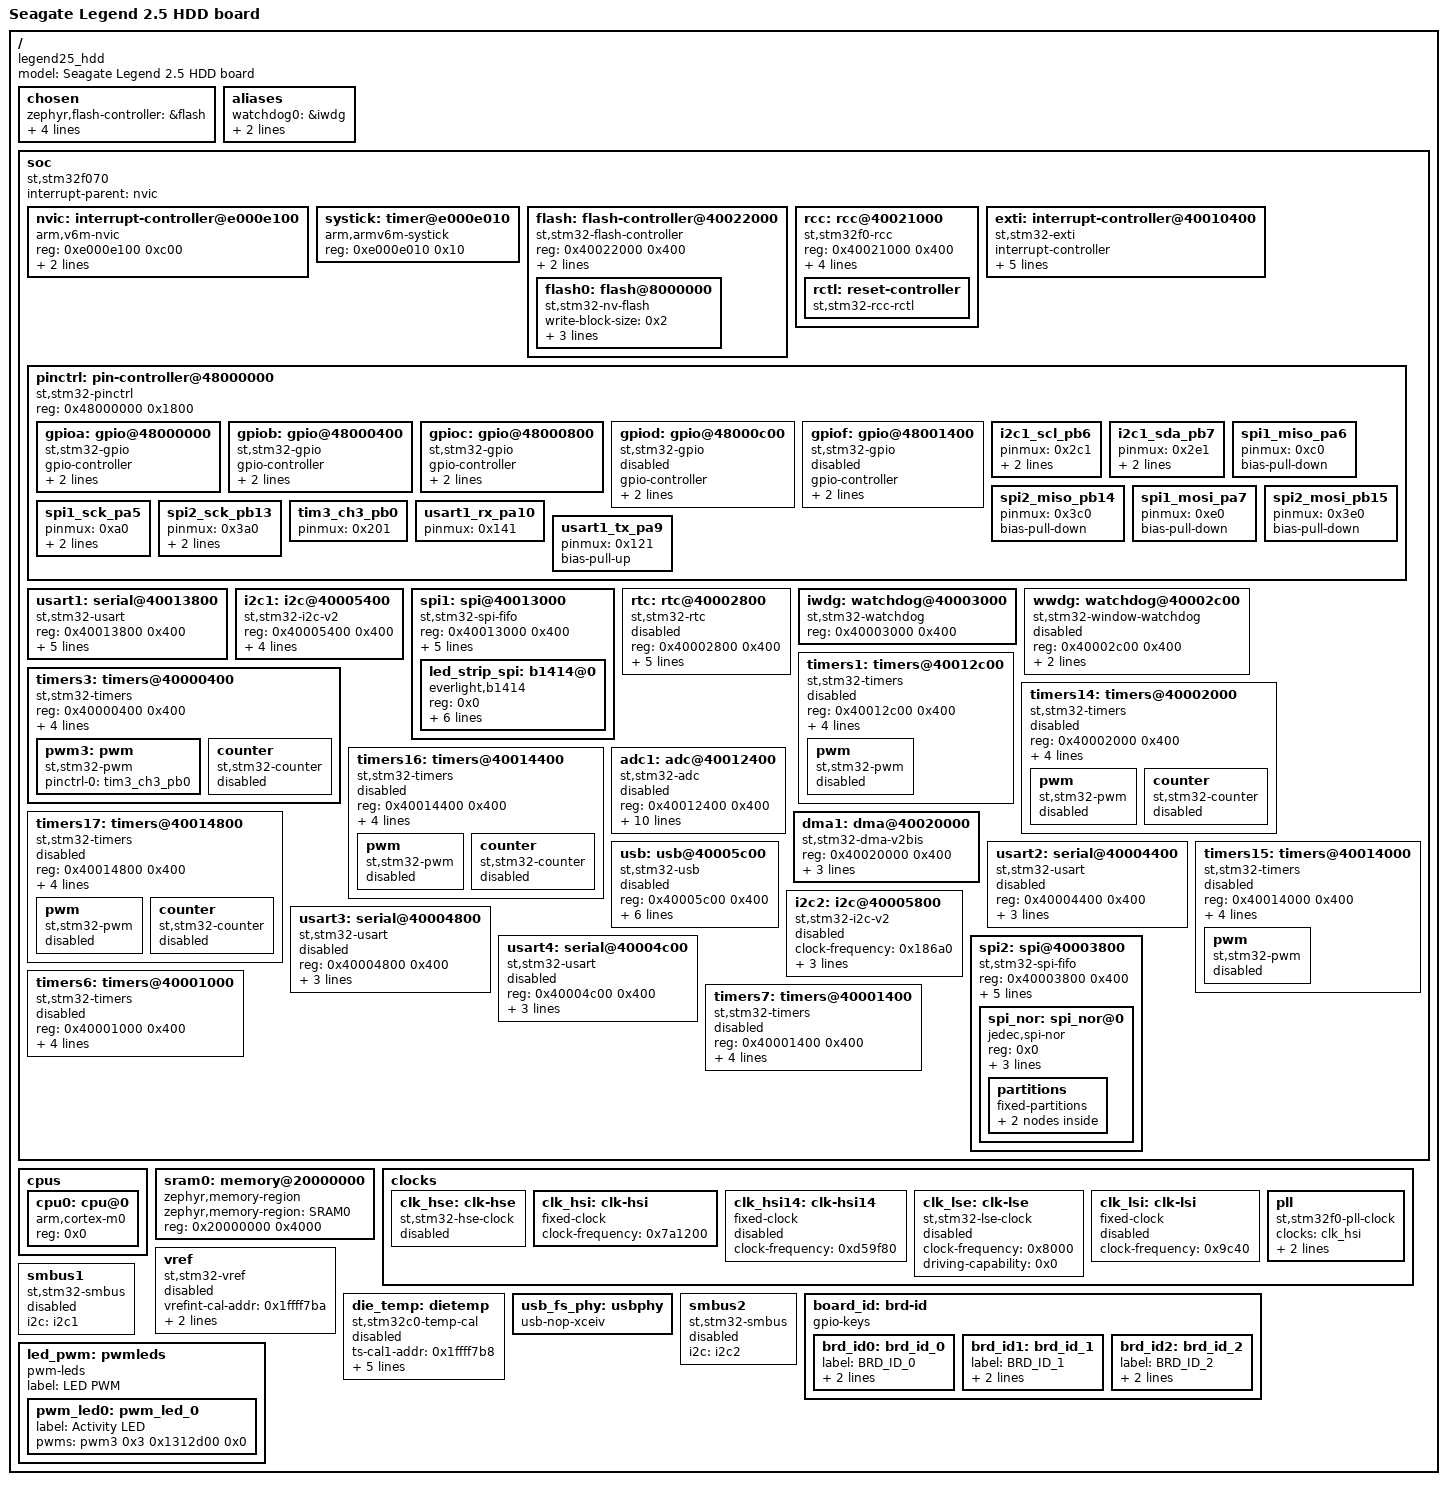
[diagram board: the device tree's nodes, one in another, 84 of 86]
/dts-v1/;

/* node '/' defined in zephyr/dts/common/skeleton.dtsi:9 */
/ {
	#address-cells = < 0x1 >;               /* in zephyr/dts/common/skeleton.dtsi:10 */
	#size-cells = < 0x1 >;                  /* in zephyr/dts/common/skeleton.dtsi:11 */
	model = "Seagate Legend 2.5 HDD board"; /* in zephyr/boards/seagate/legend/legend_stm32f070xb_25hdd.overlay:8 */
	compatible = "legend25_hdd",
	             "seagate,legend25_hdd";    /* in zephyr/boards/seagate/legend/legend_stm32f070xb_25hdd.overlay:9 */

	/* node '/chosen' defined in zephyr/dts/common/skeleton.dtsi:13 */
	chosen {
		zephyr,flash-controller = &flash; /* in zephyr/dts/arm/st/f0/stm32f0.dtsi:24 */
		zephyr,console = &usart1;         /* in zephyr/boards/seagate/legend/legend.dts:16 */
		zephyr,shell-uart = &usart1;      /* in zephyr/boards/seagate/legend/legend.dts:17 */
		zephyr,sram = &sram0;             /* in zephyr/boards/seagate/legend/legend.dts:18 */
		zephyr,flash = &flash0;           /* in zephyr/boards/seagate/legend/legend.dts:19 */
	};

	/* node '/aliases' defined in zephyr/dts/common/skeleton.dtsi:15 */
	aliases {
		watchdog0 = &iwdg;          /* in zephyr/boards/seagate/legend/legend.dts:23 */
		led-strip = &led_strip_spi; /* in zephyr/boards/seagate/legend/legend.dts:24 */
		pwm-led0 = &pwm_led0;       /* in zephyr/boards/seagate/legend/legend_stm32f070xb_25hdd.overlay:12 */
	};

	/* node '/soc' defined in zephyr/dts/arm/armv6-m.dtsi:6 */
	soc {
		#address-cells = < 0x1 >;     /* in zephyr/dts/arm/armv6-m.dtsi:7 */
		#size-cells = < 0x1 >;        /* in zephyr/dts/arm/armv6-m.dtsi:8 */
		interrupt-parent = < &nvic >; /* in zephyr/dts/arm/armv6-m.dtsi:10 */
		ranges;                       /* in zephyr/dts/arm/armv6-m.dtsi:11 */
		compatible = "st,stm32f070",
		             "st,stm32f0",
		             "simple-bus";    /* in zephyr/dts/arm/st/f0/stm32f070.dtsi:11 */

		/* node '/soc/interrupt-controller@e000e100' defined in zephyr/dts/arm/armv6-m.dtsi:13 */
		nvic: interrupt-controller@e000e100 {
			#address-cells = < 0x1 >;            /* in zephyr/dts/arm/armv6-m.dtsi:14 */
			compatible = "arm,v6m-nvic";         /* in zephyr/dts/arm/armv6-m.dtsi:15 */
			reg = < 0xe000e100 0xc00 >;          /* in zephyr/dts/arm/armv6-m.dtsi:16 */
			interrupt-controller;                /* in zephyr/dts/arm/armv6-m.dtsi:17 */
			#interrupt-cells = < 0x2 >;          /* in zephyr/dts/arm/armv6-m.dtsi:18 */
			arm,num-irq-priority-bits = < 0x2 >; /* in zephyr/dts/arm/st/f0/stm32f0.dtsi:393 */
			phandle = < 0x1 >;                   /* in zephyr/dts/arm/armv6-m.dtsi:10 */
		};

		/* node '/soc/timer@e000e010' defined in zephyr/dts/arm/armv6-m.dtsi:21 */
		systick: timer@e000e010 {
			compatible = "arm,armv6m-systick"; /* in zephyr/dts/arm/armv6-m.dtsi:22 */
			reg = < 0xe000e010 0x10 >;         /* in zephyr/dts/arm/armv6-m.dtsi:23 */
		};

		/* node '/soc/flash-controller@40022000' defined in zephyr/dts/arm/st/f0/stm32f0.dtsi:87 */
		flash: flash-controller@40022000 {
			compatible = "st,stm32-flash-controller",
			             "st,stm32f1-flash-controller"; /* in zephyr/dts/arm/st/f0/stm32f0.dtsi:88 */
			reg = < 0x40022000 0x400 >;                 /* in zephyr/dts/arm/st/f0/stm32f0.dtsi:89 */
			interrupts = < 0x3 0x0 >;                   /* in zephyr/dts/arm/st/f0/stm32f0.dtsi:90 */
			clocks = < &rcc 0x14 0x10 >;                /* in zephyr/dts/arm/st/f0/stm32f0.dtsi:91 */
			#address-cells = < 0x1 >;                   /* in zephyr/dts/arm/st/f0/stm32f0.dtsi:93 */
			#size-cells = < 0x1 >;                      /* in zephyr/dts/arm/st/f0/stm32f0.dtsi:94 */

			/* node '/soc/flash-controller@40022000/flash@8000000' defined in zephyr/dts/arm/st/f0/stm32f0.dtsi:96 */
			flash0: flash@8000000 {
				compatible = "st,stm32-nv-flash",
				             "soc-nv-flash";      /* in zephyr/dts/arm/st/f0/stm32f0.dtsi:97 */
				write-block-size = < 0x2 >;       /* in zephyr/dts/arm/st/f0/stm32f0.dtsi:99 */
				max-erase-time = < 0x28 >;        /* in zephyr/dts/arm/st/f0/stm32f0.dtsi:101 */
				erase-block-size = < 0x800 >;     /* in zephyr/dts/arm/st/f0/stm32f070Xb.dtsi:16 */
				reg = < 0x8000000 0x20000 >;      /* in zephyr/dts/arm/st/f0/stm32f070Xb.dtsi:17 */
			};
		};

		/* node '/soc/rcc@40021000' defined in zephyr/dts/arm/st/f0/stm32f0.dtsi:105 */
		rcc: rcc@40021000 {
			compatible = "st,stm32f0-rcc";   /* in zephyr/dts/arm/st/f0/stm32f0.dtsi:106 */
			#clock-cells = < 0x2 >;          /* in zephyr/dts/arm/st/f0/stm32f0.dtsi:107 */
			reg = < 0x40021000 0x400 >;      /* in zephyr/dts/arm/st/f0/stm32f0.dtsi:108 */
			clocks = < &pll >;               /* in zephyr/boards/seagate/legend/legend_stm32f070xb_25hdd.overlay:38 */
			clock-frequency = < 0x2dc6c00 >; /* in zephyr/boards/seagate/legend/legend_stm32f070xb_25hdd.overlay:39 */
			ahb-prescaler = < 0x1 >;         /* in zephyr/boards/seagate/legend/legend_stm32f070xb_25hdd.overlay:40 */
			apb1-prescaler = < 0x1 >;        /* in zephyr/boards/seagate/legend/legend_stm32f070xb_25hdd.overlay:41 */
			phandle = < 0x2 >;               /* in zephyr/dts/arm/st/f0/stm32f0.dtsi:91 */

			/* node '/soc/rcc@40021000/reset-controller' defined in zephyr/dts/arm/st/f0/stm32f0.dtsi:110 */
			rctl: reset-controller {
				compatible = "st,stm32-rcc-rctl"; /* in zephyr/dts/arm/st/f0/stm32f0.dtsi:111 */
				#reset-cells = < 0x1 >;           /* in zephyr/dts/arm/st/f0/stm32f0.dtsi:112 */
				phandle = < 0x4 >;                /* in zephyr/dts/arm/st/f0/stm32f0.dtsi:180 */
			};
		};

		/* node '/soc/interrupt-controller@40010400' defined in zephyr/dts/arm/st/f0/stm32f0.dtsi:116 */
		exti: interrupt-controller@40010400 {
			compatible = "st,stm32-exti"; /* in zephyr/dts/arm/st/f0/stm32f0.dtsi:117 */
			interrupt-controller;         /* in zephyr/dts/arm/st/f0/stm32f0.dtsi:118 */
			#interrupt-cells = < 0x1 >;   /* in zephyr/dts/arm/st/f0/stm32f0.dtsi:119 */
			#address-cells = < 0x0 >;     /* in zephyr/dts/arm/st/f0/stm32f0.dtsi:120 */
			reg = < 0x40010400 0x400 >;   /* in zephyr/dts/arm/st/f0/stm32f0.dtsi:121 */
			clocks = < &rcc 0x18 0x1 >;   /* in zephyr/dts/arm/st/f0/stm32f0.dtsi:122 */
			num-lines = < 0x20 >;         /* in zephyr/dts/arm/st/f0/stm32f0.dtsi:123 */
			interrupts = < 0x5 0x0 >,
			             < 0x6 0x0 >,
			             < 0x7 0x0 >;     /* in zephyr/dts/arm/st/f0/stm32f0.dtsi:124 */
			interrupt-names = "line0-1",
			                  "line2-3",
			                  "line4-15"; /* in zephyr/dts/arm/st/f0/stm32f0.dtsi:125 */
			line-ranges = < 0x0 0x2 >,
			              < 0x2 0x2 >,
			              < 0x4 0xc >;    /* in zephyr/dts/arm/st/f0/stm32f0.dtsi:126 */
		};

		/* node '/soc/pin-controller@48000000' defined in zephyr/dts/arm/st/f0/stm32f0.dtsi:129 */
		pinctrl: pin-controller@48000000 {
			compatible = "st,stm32-pinctrl"; /* in zephyr/dts/arm/st/f0/stm32f0.dtsi:130 */
			#address-cells = < 0x1 >;        /* in zephyr/dts/arm/st/f0/stm32f0.dtsi:131 */
			#size-cells = < 0x1 >;           /* in zephyr/dts/arm/st/f0/stm32f0.dtsi:132 */
			reg = < 0x48000000 0x1800 >;     /* in zephyr/dts/arm/st/f0/stm32f0.dtsi:133 */

			/* node '/soc/pin-controller@48000000/gpio@48000000' defined in zephyr/dts/arm/st/f0/stm32f0.dtsi:135 */
			gpioa: gpio@48000000 {
				compatible = "st,stm32-gpio";   /* in zephyr/dts/arm/st/f0/stm32f0.dtsi:136 */
				gpio-controller;                /* in zephyr/dts/arm/st/f0/stm32f0.dtsi:137 */
				#gpio-cells = < 0x2 >;          /* in zephyr/dts/arm/st/f0/stm32f0.dtsi:138 */
				reg = < 0x48000000 0x400 >;     /* in zephyr/dts/arm/st/f0/stm32f0.dtsi:139 */
				clocks = < &rcc 0x14 0x20000 >; /* in zephyr/dts/arm/st/f0/stm32f0.dtsi:140 */
			};

			/* node '/soc/pin-controller@48000000/gpio@48000400' defined in zephyr/dts/arm/st/f0/stm32f0.dtsi:143 */
			gpiob: gpio@48000400 {
				compatible = "st,stm32-gpio";   /* in zephyr/dts/arm/st/f0/stm32f0.dtsi:144 */
				gpio-controller;                /* in zephyr/dts/arm/st/f0/stm32f0.dtsi:145 */
				#gpio-cells = < 0x2 >;          /* in zephyr/dts/arm/st/f0/stm32f0.dtsi:146 */
				reg = < 0x48000400 0x400 >;     /* in zephyr/dts/arm/st/f0/stm32f0.dtsi:147 */
				clocks = < &rcc 0x14 0x40000 >; /* in zephyr/dts/arm/st/f0/stm32f0.dtsi:148 */
				phandle = < 0x12 >;             /* in zephyr/boards/seagate/legend/legend.dts:91 */
			};

			/* node '/soc/pin-controller@48000000/gpio@48000800' defined in zephyr/dts/arm/st/f0/stm32f0.dtsi:151 */
			gpioc: gpio@48000800 {
				compatible = "st,stm32-gpio";   /* in zephyr/dts/arm/st/f0/stm32f0.dtsi:152 */
				gpio-controller;                /* in zephyr/dts/arm/st/f0/stm32f0.dtsi:153 */
				#gpio-cells = < 0x2 >;          /* in zephyr/dts/arm/st/f0/stm32f0.dtsi:154 */
				reg = < 0x48000800 0x400 >;     /* in zephyr/dts/arm/st/f0/stm32f0.dtsi:155 */
				clocks = < &rcc 0x14 0x80000 >; /* in zephyr/dts/arm/st/f0/stm32f0.dtsi:156 */
				phandle = < 0x17 >;             /* in zephyr/boards/seagate/legend/legend.dts:32 */
			};

			/* node '/soc/pin-controller@48000000/gpio@48000c00' defined in zephyr/dts/arm/st/f0/stm32f0.dtsi:159 */
			gpiod: gpio@48000c00 {
				compatible = "st,stm32-gpio";    /* in zephyr/dts/arm/st/f0/stm32f0.dtsi:160 */
				gpio-controller;                 /* in zephyr/dts/arm/st/f0/stm32f0.dtsi:161 */
				#gpio-cells = < 0x2 >;           /* in zephyr/dts/arm/st/f0/stm32f0.dtsi:162 */
				reg = < 0x48000c00 0x400 >;      /* in zephyr/dts/arm/st/f0/stm32f0.dtsi:163 */
				clocks = < &rcc 0x14 0x100000 >; /* in zephyr/dts/arm/st/f0/stm32f0.dtsi:164 */
				status = "disabled";             /* in zephyr/boards/seagate/legend/legend.dts:195 */
			};

			/* node '/soc/pin-controller@48000000/gpio@48001400' defined in zephyr/dts/arm/st/f0/stm32f0.dtsi:167 */
			gpiof: gpio@48001400 {
				compatible = "st,stm32-gpio";    /* in zephyr/dts/arm/st/f0/stm32f0.dtsi:168 */
				gpio-controller;                 /* in zephyr/dts/arm/st/f0/stm32f0.dtsi:169 */
				#gpio-cells = < 0x2 >;           /* in zephyr/dts/arm/st/f0/stm32f0.dtsi:170 */
				reg = < 0x48001400 0x400 >;      /* in zephyr/dts/arm/st/f0/stm32f0.dtsi:171 */
				clocks = < &rcc 0x14 0x400000 >; /* in zephyr/dts/arm/st/f0/stm32f0.dtsi:172 */
				status = "disabled";             /* in zephyr/boards/seagate/legend/legend.dts:199 */
			};

			/* node '/soc/pin-controller@48000000/i2c1_scl_pb6' defined in modules/hal/stm32/dts/st/f0/stm32f070cbtx-pinctrl.dtsi:207 */
			i2c1_scl_pb6: i2c1_scl_pb6 {
				pinmux = < 0x2c1 >; /* in modules/hal/stm32/dts/st/f0/stm32f070cbtx-pinctrl.dtsi:208 */
				bias-pull-up;       /* in modules/hal/stm32/dts/st/f0/stm32f070cbtx-pinctrl.dtsi:209 */
				drive-open-drain;   /* in modules/hal/stm32/dts/st/f0/stm32f070cbtx-pinctrl.dtsi:210 */
				phandle = < 0x7 >;  /* in zephyr/boards/seagate/legend/legend.dts:58 */
			};

			/* node '/soc/pin-controller@48000000/i2c1_sda_pb7' defined in modules/hal/stm32/dts/st/f0/stm32f070cbtx-pinctrl.dtsi:233 */
			i2c1_sda_pb7: i2c1_sda_pb7 {
				pinmux = < 0x2e1 >; /* in modules/hal/stm32/dts/st/f0/stm32f070cbtx-pinctrl.dtsi:234 */
				bias-pull-up;       /* in modules/hal/stm32/dts/st/f0/stm32f070cbtx-pinctrl.dtsi:235 */
				drive-open-drain;   /* in modules/hal/stm32/dts/st/f0/stm32f070cbtx-pinctrl.dtsi:236 */
				phandle = < 0x8 >;  /* in zephyr/boards/seagate/legend/legend.dts:58 */
			};

			/* node '/soc/pin-controller@48000000/spi1_miso_pa6' defined in modules/hal/stm32/dts/st/f0/stm32f070cbtx-pinctrl.dtsi:283 */
			spi1_miso_pa6: spi1_miso_pa6 {
				pinmux = < 0xc0 >; /* in modules/hal/stm32/dts/st/f0/stm32f070cbtx-pinctrl.dtsi:284 */
				bias-pull-down;    /* in modules/hal/stm32/dts/st/f0/stm32f070cbtx-pinctrl.dtsi:285 */
				phandle = < 0xa >; /* in zephyr/boards/seagate/legend/legend.dts:65 */
			};

			/* node '/soc/pin-controller@48000000/spi2_miso_pb14' defined in modules/hal/stm32/dts/st/f0/stm32f070cbtx-pinctrl.dtsi:293 */
			spi2_miso_pb14: spi2_miso_pb14 {
				pinmux = < 0x3c0 >; /* in modules/hal/stm32/dts/st/f0/stm32f070cbtx-pinctrl.dtsi:294 */
				bias-pull-down;     /* in modules/hal/stm32/dts/st/f0/stm32f070cbtx-pinctrl.dtsi:295 */
				phandle = < 0x10 >; /* in zephyr/boards/seagate/legend/legend.dts:89 */
			};

			/* node '/soc/pin-controller@48000000/spi1_mosi_pa7' defined in modules/hal/stm32/dts/st/f0/stm32f070cbtx-pinctrl.dtsi:300 */
			spi1_mosi_pa7: spi1_mosi_pa7 {
				pinmux = < 0xe0 >; /* in modules/hal/stm32/dts/st/f0/stm32f070cbtx-pinctrl.dtsi:301 */
				bias-pull-down;    /* in modules/hal/stm32/dts/st/f0/stm32f070cbtx-pinctrl.dtsi:302 */
				phandle = < 0xb >; /* in zephyr/boards/seagate/legend/legend.dts:65 */
			};

			/* node '/soc/pin-controller@48000000/spi2_mosi_pb15' defined in modules/hal/stm32/dts/st/f0/stm32f070cbtx-pinctrl.dtsi:310 */
			spi2_mosi_pb15: spi2_mosi_pb15 {
				pinmux = < 0x3e0 >; /* in modules/hal/stm32/dts/st/f0/stm32f070cbtx-pinctrl.dtsi:311 */
				bias-pull-down;     /* in modules/hal/stm32/dts/st/f0/stm32f070cbtx-pinctrl.dtsi:312 */
				phandle = < 0x11 >; /* in zephyr/boards/seagate/legend/legend.dts:89 */
			};

			/* node '/soc/pin-controller@48000000/spi1_sck_pa5' defined in modules/hal/stm32/dts/st/f0/stm32f070cbtx-pinctrl.dtsi:339 */
			spi1_sck_pa5: spi1_sck_pa5 {
				pinmux = < 0xa0 >;             /* in modules/hal/stm32/dts/st/f0/stm32f070cbtx-pinctrl.dtsi:340 */
				bias-pull-down;                /* in modules/hal/stm32/dts/st/f0/stm32f070cbtx-pinctrl.dtsi:341 */
				slew-rate = "very-high-speed"; /* in modules/hal/stm32/dts/st/f0/stm32f070cbtx-pinctrl.dtsi:342 */
				phandle = < 0x9 >;             /* in zephyr/boards/seagate/legend/legend.dts:65 */
			};

			/* node '/soc/pin-controller@48000000/spi2_sck_pb13' defined in modules/hal/stm32/dts/st/f0/stm32f070cbtx-pinctrl.dtsi:357 */
			spi2_sck_pb13: spi2_sck_pb13 {
				pinmux = < 0x3a0 >;            /* in modules/hal/stm32/dts/st/f0/stm32f070cbtx-pinctrl.dtsi:358 */
				bias-pull-down;                /* in modules/hal/stm32/dts/st/f0/stm32f070cbtx-pinctrl.dtsi:359 */
				slew-rate = "very-high-speed"; /* in modules/hal/stm32/dts/st/f0/stm32f070cbtx-pinctrl.dtsi:360 */
				phandle = < 0xf >;             /* in zephyr/boards/seagate/legend/legend.dts:89 */
			};

			/* node '/soc/pin-controller@48000000/tim3_ch3_pb0' defined in modules/hal/stm32/dts/st/f0/stm32f070cbtx-pinctrl.dtsi:443 */
			tim3_ch3_pb0: tim3_ch3_pb0 {
				pinmux = < 0x201 >; /* in modules/hal/stm32/dts/st/f0/stm32f070cbtx-pinctrl.dtsi:444 */
				phandle = < 0xd >;  /* in zephyr/boards/seagate/legend/legend.dts:188 */
			};

			/* node '/soc/pin-controller@48000000/usart1_rx_pa10' defined in modules/hal/stm32/dts/st/f0/stm32f070cbtx-pinctrl.dtsi:602 */
			usart1_rx_pa10: usart1_rx_pa10 {
				pinmux = < 0x141 >; /* in modules/hal/stm32/dts/st/f0/stm32f070cbtx-pinctrl.dtsi:603 */
				phandle = < 0x6 >;  /* in zephyr/boards/seagate/legend/legend.dts:51 */
			};

			/* node '/soc/pin-controller@48000000/usart1_tx_pa9' defined in modules/hal/stm32/dts/st/f0/stm32f070cbtx-pinctrl.dtsi:628 */
			usart1_tx_pa9: usart1_tx_pa9 {
				pinmux = < 0x121 >; /* in modules/hal/stm32/dts/st/f0/stm32f070cbtx-pinctrl.dtsi:629 */
				bias-pull-up;       /* in modules/hal/stm32/dts/st/f0/stm32f070cbtx-pinctrl.dtsi:630 */
				phandle = < 0x5 >;  /* in zephyr/boards/seagate/legend/legend.dts:51 */
			};
		};

		/* node '/soc/serial@40013800' defined in zephyr/dts/arm/st/f0/stm32f0.dtsi:176 */
		usart1: serial@40013800 {
			compatible = "st,stm32-usart",
			             "st,stm32-uart";                   /* in zephyr/dts/arm/st/f0/stm32f0.dtsi:177 */
			reg = < 0x40013800 0x400 >;                     /* in zephyr/dts/arm/st/f0/stm32f0.dtsi:178 */
			clocks = < &rcc 0x18 0x4000 >;                  /* in zephyr/dts/arm/st/f0/stm32f0.dtsi:179 */
			resets = < &rctl 0x18e >;                       /* in zephyr/dts/arm/st/f0/stm32f0.dtsi:180 */
			interrupts = < 0x1b 0x0 >;                      /* in zephyr/dts/arm/st/f0/stm32f0.dtsi:181 */
			pinctrl-0 = < &usart1_tx_pa9 &usart1_rx_pa10 >; /* in zephyr/boards/seagate/legend/legend.dts:51 */
			pinctrl-names = "default";                      /* in zephyr/boards/seagate/legend/legend.dts:52 */
			current-speed = < 0x1c200 >;                    /* in zephyr/boards/seagate/legend/legend.dts:53 */
			status = "okay";                                /* in zephyr/boards/seagate/legend/legend.dts:54 */
		};

		/* node '/soc/i2c@40005400' defined in zephyr/dts/arm/st/f0/stm32f0.dtsi:185 */
		i2c1: i2c@40005400 {
			compatible = "st,stm32-i2c-v2";              /* in zephyr/dts/arm/st/f0/stm32f0.dtsi:186 */
			#address-cells = < 0x1 >;                    /* in zephyr/dts/arm/st/f0/stm32f0.dtsi:188 */
			#size-cells = < 0x0 >;                       /* in zephyr/dts/arm/st/f0/stm32f0.dtsi:189 */
			reg = < 0x40005400 0x400 >;                  /* in zephyr/dts/arm/st/f0/stm32f0.dtsi:190 */
			clocks = < &rcc 0x1c 0x200000 >,
			         < &rcc 0x1 0x1040030 >;             /* in zephyr/dts/arm/st/f0/stm32f0.dtsi:191 */
			interrupts = < 0x17 0x0 >;                   /* in zephyr/dts/arm/st/f0/stm32f0.dtsi:196 */
			interrupt-names = "combined";                /* in zephyr/dts/arm/st/f0/stm32f0.dtsi:197 */
			pinctrl-0 = < &i2c1_scl_pb6 &i2c1_sda_pb7 >; /* in zephyr/boards/seagate/legend/legend.dts:58 */
			pinctrl-names = "default";                   /* in zephyr/boards/seagate/legend/legend.dts:59 */
			clock-frequency = < 0x186a0 >;               /* in zephyr/boards/seagate/legend/legend.dts:60 */
			status = "okay";                             /* in zephyr/boards/seagate/legend/legend.dts:61 */
			phandle = < 0x15 >;                          /* in zephyr/dts/arm/st/f0/stm32f0.dtsi:387 */
		};

		/* node '/soc/spi@40013000' defined in zephyr/dts/arm/st/f0/stm32f0.dtsi:201 */
		spi1: spi@40013000 {
			compatible = "st,stm32-spi-fifo",
			             "st,stm32-spi";                                 /* in zephyr/dts/arm/st/f0/stm32f0.dtsi:202 */
			#address-cells = < 0x1 >;                                    /* in zephyr/dts/arm/st/f0/stm32f0.dtsi:203 */
			#size-cells = < 0x0 >;                                       /* in zephyr/dts/arm/st/f0/stm32f0.dtsi:204 */
			reg = < 0x40013000 0x400 >;                                  /* in zephyr/dts/arm/st/f0/stm32f0.dtsi:205 */
			clocks = < &rcc 0x18 0x1000 >;                               /* in zephyr/dts/arm/st/f0/stm32f0.dtsi:206 */
			interrupts = < 0x19 0x3 >;                                   /* in zephyr/dts/arm/st/f0/stm32f0.dtsi:207 */
			pinctrl-0 = < &spi1_sck_pa5 &spi1_miso_pa6 &spi1_mosi_pa7 >; /* in zephyr/boards/seagate/legend/legend.dts:65 */
			pinctrl-names = "default";                                   /* in zephyr/boards/seagate/legend/legend.dts:66 */
			dmas = < &dma1 0x3 0x20440 >,
			       < &dma1 0x2 0x20480 >;                                /* in zephyr/boards/seagate/legend/legend.dts:67 */
			dma-names = "tx",
			            "rx";                                            /* in zephyr/boards/seagate/legend/legend.dts:68 */
			status = "okay";                                             /* in zephyr/boards/seagate/legend/legend.dts:69 */

			/* node '/soc/spi@40013000/b1414@0' defined in zephyr/boards/seagate/legend/legend.dts:71 */
			led_strip_spi: b1414@0 {
				compatible = "everlight,b1414",
				             "worldsemi,ws2812-spi"; /* in zephyr/boards/seagate/legend/legend.dts:72 */
				reg = < 0x0 >;                       /* in zephyr/boards/seagate/legend/legend.dts:75 */
				spi-max-frequency = < 0x5b8d80 >;    /* in zephyr/boards/seagate/legend/legend.dts:76 */
				spi-one-frame = < 0x7c >;            /* in zephyr/boards/seagate/legend/legend.dts:79 */
				spi-zero-frame = < 0x60 >;           /* in zephyr/boards/seagate/legend/legend.dts:80 */
				color-mapping = < 0x1 >,
				                < 0x2 >,
				                < 0x3 >;             /* in zephyr/boards/seagate/legend/legend.dts:81 */
				reset-delay = < 0xfa >;              /* in zephyr/boards/seagate/legend/legend.dts:84 */
				chain-length = < 0x6 >;              /* in zephyr/boards/seagate/legend/legend_stm32f070xb_25hdd.overlay:45 */
				status = "okay";                     /* in zephyr/boards/seagate/legend/legend_stm32f070xb_25hdd.overlay:46 */
			};
		};

		/* node '/soc/rtc@40002800' defined in zephyr/dts/arm/st/f0/stm32f0.dtsi:211 */
		rtc: rtc@40002800 {
			compatible = "st,stm32-rtc";       /* in zephyr/dts/arm/st/f0/stm32f0.dtsi:212 */
			reg = < 0x40002800 0x400 >;        /* in zephyr/dts/arm/st/f0/stm32f0.dtsi:213 */
			clocks = < &rcc 0x1c 0x10000000 >; /* in zephyr/dts/arm/st/f0/stm32f0.dtsi:214 */
			interrupts = < 0x2 0x0 >;          /* in zephyr/dts/arm/st/f0/stm32f0.dtsi:215 */
			prescaler = < 0x8000 >;            /* in zephyr/dts/arm/st/f0/stm32f0.dtsi:216 */
			alarms-count = < 0x1 >;            /* in zephyr/dts/arm/st/f0/stm32f0.dtsi:217 */
			alrm-exti-line = < 0x11 >;         /* in zephyr/dts/arm/st/f0/stm32f0.dtsi:218 */
			status = "disabled";               /* in zephyr/dts/arm/st/f0/stm32f0.dtsi:219 */
		};

		/* node '/soc/watchdog@40003000' defined in zephyr/dts/arm/st/f0/stm32f0.dtsi:222 */
		iwdg: watchdog@40003000 {
			compatible = "st,stm32-watchdog"; /* in zephyr/dts/arm/st/f0/stm32f0.dtsi:223 */
			reg = < 0x40003000 0x400 >;       /* in zephyr/dts/arm/st/f0/stm32f0.dtsi:224 */
			status = "okay";                  /* in zephyr/boards/seagate/legend/legend.dts:203 */
		};

		/* node '/soc/watchdog@40002c00' defined in zephyr/dts/arm/st/f0/stm32f0.dtsi:228 */
		wwdg: watchdog@40002c00 {
			compatible = "st,stm32-window-watchdog"; /* in zephyr/dts/arm/st/f0/stm32f0.dtsi:229 */
			reg = < 0x40002c00 0x400 >;              /* in zephyr/dts/arm/st/f0/stm32f0.dtsi:230 */
			clocks = < &rcc 0x1c 0x800 >;            /* in zephyr/dts/arm/st/f0/stm32f0.dtsi:231 */
			interrupts = < 0x0 0x2 >;                /* in zephyr/dts/arm/st/f0/stm32f0.dtsi:232 */
			status = "disabled";                     /* in zephyr/dts/arm/st/f0/stm32f0.dtsi:233 */
		};

		/* node '/soc/timers@40012c00' defined in zephyr/dts/arm/st/f0/stm32f0.dtsi:236 */
		timers1: timers@40012c00 {
			compatible = "st,stm32-timers";     /* in zephyr/dts/arm/st/f0/stm32f0.dtsi:237 */
			reg = < 0x40012c00 0x400 >;         /* in zephyr/dts/arm/st/f0/stm32f0.dtsi:238 */
			clocks = < &rcc 0x18 0x800 >,
			         < &rcc 0x8 0xff >;         /* in zephyr/dts/arm/st/f0/stm32f0.dtsi:239 */
			resets = < &rctl 0x18b >;           /* in zephyr/dts/arm/st/f0/stm32f0.dtsi:241 */
			interrupts = < 0xd 0x0 >,
			             < 0xe 0x0 >;           /* in zephyr/dts/arm/st/f0/stm32f0.dtsi:242 */
			interrupt-names = "brk_up_trg_com",
			                  "cc";             /* in zephyr/dts/arm/st/f0/stm32f0.dtsi:243 */
			st,prescaler = < 0x0 >;             /* in zephyr/dts/arm/st/f0/stm32f0.dtsi:244 */
			status = "disabled";                /* in zephyr/dts/arm/st/f0/stm32f0.dtsi:245 */

			/* node '/soc/timers@40012c00/pwm' defined in zephyr/dts/arm/st/f0/stm32f0.dtsi:247 */
			pwm {
				compatible = "st,stm32-pwm"; /* in zephyr/dts/arm/st/f0/stm32f0.dtsi:248 */
				status = "disabled";         /* in zephyr/dts/arm/st/f0/stm32f0.dtsi:249 */
				#pwm-cells = < 0x3 >;        /* in zephyr/dts/arm/st/f0/stm32f0.dtsi:250 */
			};
		};

		/* node '/soc/timers@40000400' defined in zephyr/dts/arm/st/f0/stm32f0.dtsi:254 */
		timers3: timers@40000400 {
			compatible = "st,stm32-timers"; /* in zephyr/dts/arm/st/f0/stm32f0.dtsi:255 */
			reg = < 0x40000400 0x400 >;     /* in zephyr/dts/arm/st/f0/stm32f0.dtsi:256 */
			clocks = < &rcc 0x1c 0x2 >,
			         < &rcc 0x8 0xff >;     /* in zephyr/dts/arm/st/f0/stm32f0.dtsi:257 */
			resets = < &rctl 0x201 >;       /* in zephyr/dts/arm/st/f0/stm32f0.dtsi:259 */
			interrupts = < 0x10 0x0 >;      /* in zephyr/dts/arm/st/f0/stm32f0.dtsi:260 */
			interrupt-names = "global";     /* in zephyr/dts/arm/st/f0/stm32f0.dtsi:261 */
			st,prescaler = < 0xc8 >;        /* in zephyr/boards/seagate/legend/legend.dts:185 */
			status = "okay";                /* in zephyr/boards/seagate/legend/legend_stm32f070xb_25hdd.overlay:50 */

			/* node '/soc/timers@40000400/pwm' defined in zephyr/dts/arm/st/f0/stm32f0.dtsi:265 */
			pwm3: pwm {
				compatible = "st,stm32-pwm";   /* in zephyr/dts/arm/st/f0/stm32f0.dtsi:266 */
				#pwm-cells = < 0x3 >;          /* in zephyr/dts/arm/st/f0/stm32f0.dtsi:268 */
				pinctrl-0 = < &tim3_ch3_pb0 >; /* in zephyr/boards/seagate/legend/legend.dts:188 */
				pinctrl-names = "default";     /* in zephyr/boards/seagate/legend/legend.dts:189 */
				status = "okay";               /* in zephyr/boards/seagate/legend/legend_stm32f070xb_25hdd.overlay:54 */
				phandle = < 0x18 >;            /* in zephyr/boards/seagate/legend/legend_stm32f070xb_25hdd.overlay:21 */
			};

			/* node '/soc/timers@40000400/counter' defined in zephyr/dts/arm/st/f0/stm32f0.dtsi:271 */
			counter {
				compatible = "st,stm32-counter"; /* in zephyr/dts/arm/st/f0/stm32f0.dtsi:272 */
				status = "disabled";             /* in zephyr/dts/arm/st/f0/stm32f0.dtsi:273 */
			};
		};

		/* node '/soc/timers@40002000' defined in zephyr/dts/arm/st/f0/stm32f0.dtsi:277 */
		timers14: timers@40002000 {
			compatible = "st,stm32-timers"; /* in zephyr/dts/arm/st/f0/stm32f0.dtsi:278 */
			reg = < 0x40002000 0x400 >;     /* in zephyr/dts/arm/st/f0/stm32f0.dtsi:279 */
			clocks = < &rcc 0x1c 0x100 >,
			         < &rcc 0x8 0xff >;     /* in zephyr/dts/arm/st/f0/stm32f0.dtsi:280 */
			resets = < &rctl 0x208 >;       /* in zephyr/dts/arm/st/f0/stm32f0.dtsi:282 */
			interrupts = < 0x13 0x0 >;      /* in zephyr/dts/arm/st/f0/stm32f0.dtsi:283 */
			interrupt-names = "global";     /* in zephyr/dts/arm/st/f0/stm32f0.dtsi:284 */
			st,prescaler = < 0x0 >;         /* in zephyr/dts/arm/st/f0/stm32f0.dtsi:285 */
			status = "disabled";            /* in zephyr/dts/arm/st/f0/stm32f0.dtsi:286 */

			/* node '/soc/timers@40002000/pwm' defined in zephyr/dts/arm/st/f0/stm32f0.dtsi:288 */
			pwm {
				compatible = "st,stm32-pwm"; /* in zephyr/dts/arm/st/f0/stm32f0.dtsi:289 */
				status = "disabled";         /* in zephyr/dts/arm/st/f0/stm32f0.dtsi:290 */
				#pwm-cells = < 0x3 >;        /* in zephyr/dts/arm/st/f0/stm32f0.dtsi:291 */
			};

			/* node '/soc/timers@40002000/counter' defined in zephyr/dts/arm/st/f0/stm32f0.dtsi:294 */
			counter {
				compatible = "st,stm32-counter"; /* in zephyr/dts/arm/st/f0/stm32f0.dtsi:295 */
				status = "disabled";             /* in zephyr/dts/arm/st/f0/stm32f0.dtsi:296 */
			};
		};

		/* node '/soc/timers@40014400' defined in zephyr/dts/arm/st/f0/stm32f0.dtsi:300 */
		timers16: timers@40014400 {
			compatible = "st,stm32-timers"; /* in zephyr/dts/arm/st/f0/stm32f0.dtsi:301 */
			reg = < 0x40014400 0x400 >;     /* in zephyr/dts/arm/st/f0/stm32f0.dtsi:302 */
			clocks = < &rcc 0x18 0x20000 >,
			         < &rcc 0x8 0xff >;     /* in zephyr/dts/arm/st/f0/stm32f0.dtsi:303 */
			resets = < &rctl 0x191 >;       /* in zephyr/dts/arm/st/f0/stm32f0.dtsi:305 */
			interrupts = < 0x15 0x0 >;      /* in zephyr/dts/arm/st/f0/stm32f0.dtsi:306 */
			interrupt-names = "global";     /* in zephyr/dts/arm/st/f0/stm32f0.dtsi:307 */
			st,prescaler = < 0x0 >;         /* in zephyr/dts/arm/st/f0/stm32f0.dtsi:308 */
			status = "disabled";            /* in zephyr/dts/arm/st/f0/stm32f0.dtsi:309 */

			/* node '/soc/timers@40014400/pwm' defined in zephyr/dts/arm/st/f0/stm32f0.dtsi:311 */
			pwm {
				compatible = "st,stm32-pwm"; /* in zephyr/dts/arm/st/f0/stm32f0.dtsi:312 */
				status = "disabled";         /* in zephyr/dts/arm/st/f0/stm32f0.dtsi:313 */
				#pwm-cells = < 0x3 >;        /* in zephyr/dts/arm/st/f0/stm32f0.dtsi:314 */
			};

			/* node '/soc/timers@40014400/counter' defined in zephyr/dts/arm/st/f0/stm32f0.dtsi:317 */
			counter {
				compatible = "st,stm32-counter"; /* in zephyr/dts/arm/st/f0/stm32f0.dtsi:318 */
				status = "disabled";             /* in zephyr/dts/arm/st/f0/stm32f0.dtsi:319 */
			};
		};

		/* node '/soc/timers@40014800' defined in zephyr/dts/arm/st/f0/stm32f0.dtsi:323 */
		timers17: timers@40014800 {
			compatible = "st,stm32-timers"; /* in zephyr/dts/arm/st/f0/stm32f0.dtsi:324 */
			reg = < 0x40014800 0x400 >;     /* in zephyr/dts/arm/st/f0/stm32f0.dtsi:325 */
			clocks = < &rcc 0x18 0x40000 >,
			         < &rcc 0x8 0xff >;     /* in zephyr/dts/arm/st/f0/stm32f0.dtsi:326 */
			resets = < &rctl 0x192 >;       /* in zephyr/dts/arm/st/f0/stm32f0.dtsi:328 */
			interrupts = < 0x16 0x0 >;      /* in zephyr/dts/arm/st/f0/stm32f0.dtsi:329 */
			interrupt-names = "global";     /* in zephyr/dts/arm/st/f0/stm32f0.dtsi:330 */
			st,prescaler = < 0x0 >;         /* in zephyr/dts/arm/st/f0/stm32f0.dtsi:331 */
			status = "disabled";            /* in zephyr/dts/arm/st/f0/stm32f0.dtsi:332 */

			/* node '/soc/timers@40014800/pwm' defined in zephyr/dts/arm/st/f0/stm32f0.dtsi:334 */
			pwm {
				compatible = "st,stm32-pwm"; /* in zephyr/dts/arm/st/f0/stm32f0.dtsi:335 */
				status = "disabled";         /* in zephyr/dts/arm/st/f0/stm32f0.dtsi:336 */
				#pwm-cells = < 0x3 >;        /* in zephyr/dts/arm/st/f0/stm32f0.dtsi:337 */
			};

			/* node '/soc/timers@40014800/counter' defined in zephyr/dts/arm/st/f0/stm32f0.dtsi:340 */
			counter {
				compatible = "st,stm32-counter"; /* in zephyr/dts/arm/st/f0/stm32f0.dtsi:341 */
				status = "disabled";             /* in zephyr/dts/arm/st/f0/stm32f0.dtsi:342 */
			};
		};

		/* node '/soc/adc@40012400' defined in zephyr/dts/arm/st/f0/stm32f0.dtsi:346 */
		adc1: adc@40012400 {
			compatible = "st,stm32-adc";                               /* in zephyr/dts/arm/st/f0/stm32f0.dtsi:347 */
			reg = < 0x40012400 0x400 >;                                /* in zephyr/dts/arm/st/f0/stm32f0.dtsi:348 */
			clocks = < &rcc 0x18 0x200 >;                              /* in zephyr/dts/arm/st/f0/stm32f0.dtsi:349 */
			clock-names = "adcx";                                      /* in zephyr/dts/arm/st/f0/stm32f0.dtsi:350 */
			interrupts = < 0xc 0x0 >;                                  /* in zephyr/dts/arm/st/f0/stm32f0.dtsi:351 */
			#io-channel-cells = < 0x1 >;                               /* in zephyr/dts/arm/st/f0/stm32f0.dtsi:352 */
			resolutions = < 0x60630c 0x51630c 0x42630c 0x33630c >;     /* in zephyr/dts/arm/st/f0/stm32f0.dtsi:353 */
			sampling-times = < 0x2 0x8 0xe 0x1d 0x2a 0x38 0x48 0xf0 >; /* in zephyr/dts/arm/st/f0/stm32f0.dtsi:357 */
			num-sampling-time-common-channels = < 0x1 >;               /* in zephyr/dts/arm/st/f0/stm32f0.dtsi:358 */
			st,adc-sequencer = "fixed";                                /* in zephyr/dts/arm/st/f0/stm32f0.dtsi:359 */
			st,adc-oversampler = "none";                               /* in zephyr/dts/arm/st/f0/stm32f0.dtsi:360 */
			st,adc-internal-regulator = "none";                        /* in zephyr/dts/arm/st/f0/stm32f0.dtsi:361 */
			status = "disabled";                                       /* in zephyr/dts/arm/st/f0/stm32f0.dtsi:362 */
			phandle = < 0x14 >;                                        /* in zephyr/dts/arm/st/f0/stm32f0.dtsi:379 */
		};

		/* node '/soc/dma@40020000' defined in zephyr/dts/arm/st/f0/stm32f0.dtsi:365 */
		dma1: dma@40020000 {
			compatible = "st,stm32-dma-v2bis";                        /* in zephyr/dts/arm/st/f0/stm32f0.dtsi:366 */
			#dma-cells = < 0x2 >;                                     /* in zephyr/dts/arm/st/f0/stm32f0.dtsi:367 */
			reg = < 0x40020000 0x400 >;                               /* in zephyr/dts/arm/st/f0/stm32f0.dtsi:368 */
			clocks = < &rcc 0x14 0x1 >;                               /* in zephyr/dts/arm/st/f0/stm32f0.dtsi:369 */
			interrupts = < 0x9 0x0 0xa 0x0 0xa 0x0 0xb 0x0 0xb 0x0 >; /* in zephyr/dts/arm/st/f0/stm32f0.dtsi:370 */
			status = "okay";                                          /* in zephyr/boards/seagate/legend/legend.dts:157 */
			phandle = < 0xc >;                                        /* in zephyr/boards/seagate/legend/legend.dts:67 */
		};

		/* node '/soc/serial@40004400' defined in zephyr/dts/arm/st/f0/stm32f070.dtsi:13 */
		usart2: serial@40004400 {
			compatible = "st,stm32-usart",
			             "st,stm32-uart";   /* in zephyr/dts/arm/st/f0/stm32f070.dtsi:14 */
			reg = < 0x40004400 0x400 >;     /* in zephyr/dts/arm/st/f0/stm32f070.dtsi:15 */
			clocks = < &rcc 0x1c 0x20000 >; /* in zephyr/dts/arm/st/f0/stm32f070.dtsi:16 */
			resets = < &rctl 0x211 >;       /* in zephyr/dts/arm/st/f0/stm32f070.dtsi:17 */
			interrupts = < 0x1c 0x0 >;      /* in zephyr/dts/arm/st/f0/stm32f070.dtsi:18 */
			status = "disabled";            /* in zephyr/dts/arm/st/f0/stm32f070.dtsi:19 */
		};

		/* node '/soc/timers@40014000' defined in zephyr/dts/arm/st/f0/stm32f070.dtsi:22 */
		timers15: timers@40014000 {
			compatible = "st,stm32-timers"; /* in zephyr/dts/arm/st/f0/stm32f070.dtsi:23 */
			reg = < 0x40014000 0x400 >;     /* in zephyr/dts/arm/st/f0/stm32f070.dtsi:24 */
			clocks = < &rcc 0x18 0x10000 >,
			         < &rcc 0x8 0xff >;     /* in zephyr/dts/arm/st/f0/stm32f070.dtsi:25 */
			resets = < &rctl 0x190 >;       /* in zephyr/dts/arm/st/f0/stm32f070.dtsi:27 */
			interrupts = < 0x14 0x0 >;      /* in zephyr/dts/arm/st/f0/stm32f070.dtsi:28 */
			interrupt-names = "global";     /* in zephyr/dts/arm/st/f0/stm32f070.dtsi:29 */
			st,prescaler = < 0x0 >;         /* in zephyr/dts/arm/st/f0/stm32f070.dtsi:30 */
			status = "disabled";            /* in zephyr/dts/arm/st/f0/stm32f070.dtsi:31 */

			/* node '/soc/timers@40014000/pwm' defined in zephyr/dts/arm/st/f0/stm32f070.dtsi:33 */
			pwm {
				compatible = "st,stm32-pwm"; /* in zephyr/dts/arm/st/f0/stm32f070.dtsi:34 */
				status = "disabled";         /* in zephyr/dts/arm/st/f0/stm32f070.dtsi:35 */
				#pwm-cells = < 0x3 >;        /* in zephyr/dts/arm/st/f0/stm32f070.dtsi:36 */
			};
		};

		/* node '/soc/usb@40005c00' defined in zephyr/dts/arm/st/f0/stm32f070.dtsi:40 */
		usb: usb@40005c00 {
			compatible = "st,stm32-usb";     /* in zephyr/dts/arm/st/f0/stm32f070.dtsi:41 */
			reg = < 0x40005c00 0x400 >;      /* in zephyr/dts/arm/st/f0/stm32f070.dtsi:42 */
			interrupts = < 0x1f 0x0 >;       /* in zephyr/dts/arm/st/f0/stm32f070.dtsi:43 */
			interrupt-names = "usb";         /* in zephyr/dts/arm/st/f0/stm32f070.dtsi:44 */
			num-bidir-endpoints = < 0x8 >;   /* in zephyr/dts/arm/st/f0/stm32f070.dtsi:45 */
			ram-size = < 0x400 >;            /* in zephyr/dts/arm/st/f0/stm32f070.dtsi:46 */
			maximum-speed = "full-speed";    /* in zephyr/dts/arm/st/f0/stm32f070.dtsi:47 */
			phys = < &usb_fs_phy >;          /* in zephyr/dts/arm/st/f0/stm32f070.dtsi:48 */
			clocks = < &rcc 0x1c 0x800000 >,
			         < &rcc 0x9 0x1070030 >; /* in zephyr/dts/arm/st/f0/stm32f070.dtsi:49 */
			status = "disabled";             /* in zephyr/dts/arm/st/f0/stm32f070.dtsi:51 */
		};

		/* node '/soc/serial@40004800' defined in zephyr/dts/arm/st/f0/stm32f070Xb.dtsi:27 */
		usart3: serial@40004800 {
			compatible = "st,stm32-usart",
			             "st,stm32-uart";   /* in zephyr/dts/arm/st/f0/stm32f070Xb.dtsi:28 */
			reg = < 0x40004800 0x400 >;     /* in zephyr/dts/arm/st/f0/stm32f070Xb.dtsi:29 */
			clocks = < &rcc 0x1c 0x40000 >; /* in zephyr/dts/arm/st/f0/stm32f070Xb.dtsi:30 */
			resets = < &rctl 0x212 >;       /* in zephyr/dts/arm/st/f0/stm32f070Xb.dtsi:31 */
			interrupts = < 0x1d 0x0 >;      /* in zephyr/dts/arm/st/f0/stm32f070Xb.dtsi:32 */
			status = "disabled";            /* in zephyr/dts/arm/st/f0/stm32f070Xb.dtsi:33 */
		};

		/* node '/soc/serial@40004c00' defined in zephyr/dts/arm/st/f0/stm32f070Xb.dtsi:36 */
		usart4: serial@40004c00 {
			compatible = "st,stm32-usart",
			             "st,stm32-uart";   /* in zephyr/dts/arm/st/f0/stm32f070Xb.dtsi:37 */
			reg = < 0x40004c00 0x400 >;     /* in zephyr/dts/arm/st/f0/stm32f070Xb.dtsi:38 */
			clocks = < &rcc 0x1c 0x80000 >; /* in zephyr/dts/arm/st/f0/stm32f070Xb.dtsi:39 */
			resets = < &rctl 0x213 >;       /* in zephyr/dts/arm/st/f0/stm32f070Xb.dtsi:40 */
			interrupts = < 0x1d 0x0 >;      /* in zephyr/dts/arm/st/f0/stm32f070Xb.dtsi:41 */
			status = "disabled";            /* in zephyr/dts/arm/st/f0/stm32f070Xb.dtsi:42 */
		};

		/* node '/soc/i2c@40005800' defined in zephyr/dts/arm/st/f0/stm32f070Xb.dtsi:45 */
		i2c2: i2c@40005800 {
			compatible = "st,stm32-i2c-v2";  /* in zephyr/dts/arm/st/f0/stm32f070Xb.dtsi:46 */
			clock-frequency = < 0x186a0 >;   /* in zephyr/dts/arm/st/f0/stm32f070Xb.dtsi:47 */
			#address-cells = < 0x1 >;        /* in zephyr/dts/arm/st/f0/stm32f070Xb.dtsi:48 */
			#size-cells = < 0x0 >;           /* in zephyr/dts/arm/st/f0/stm32f070Xb.dtsi:49 */
			reg = < 0x40005800 0x400 >;      /* in zephyr/dts/arm/st/f0/stm32f070Xb.dtsi:50 */
			clocks = < &rcc 0x1c 0x400000 >; /* in zephyr/dts/arm/st/f0/stm32f070Xb.dtsi:51 */
			interrupts = < 0x18 0x0 >;       /* in zephyr/dts/arm/st/f0/stm32f070Xb.dtsi:52 */
			interrupt-names = "combined";    /* in zephyr/dts/arm/st/f0/stm32f070Xb.dtsi:53 */
			status = "disabled";             /* in zephyr/dts/arm/st/f0/stm32f070Xb.dtsi:54 */
			phandle = < 0x16 >;              /* in zephyr/dts/arm/st/f0/stm32f070Xb.dtsi:96 */
		};

		/* node '/soc/spi@40003800' defined in zephyr/dts/arm/st/f0/stm32f070Xb.dtsi:57 */
		spi2: spi@40003800 {
			compatible = "st,stm32-spi-fifo",
			             "st,stm32-spi";                                    /* in zephyr/dts/arm/st/f0/stm32f070Xb.dtsi:58 */
			#address-cells = < 0x1 >;                                       /* in zephyr/dts/arm/st/f0/stm32f070Xb.dtsi:59 */
			#size-cells = < 0x0 >;                                          /* in zephyr/dts/arm/st/f0/stm32f070Xb.dtsi:60 */
			reg = < 0x40003800 0x400 >;                                     /* in zephyr/dts/arm/st/f0/stm32f070Xb.dtsi:61 */
			clocks = < &rcc 0x1c 0x4000 >;                                  /* in zephyr/dts/arm/st/f0/stm32f070Xb.dtsi:62 */
			interrupts = < 0x1a 0x3 >;                                      /* in zephyr/dts/arm/st/f0/stm32f070Xb.dtsi:63 */
			pinctrl-0 = < &spi2_sck_pb13 &spi2_miso_pb14 &spi2_mosi_pb15 >; /* in zephyr/boards/seagate/legend/legend.dts:89 */
			pinctrl-names = "default";                                      /* in zephyr/boards/seagate/legend/legend.dts:90 */
			cs-gpios = < &gpiob 0xc 0x1 >;                                  /* in zephyr/boards/seagate/legend/legend.dts:91 */
			status = "okay";                                                /* in zephyr/boards/seagate/legend/legend.dts:92 */

			/* node '/soc/spi@40003800/spi_nor@0' defined in zephyr/boards/seagate/legend/legend.dts:94 */
			spi_nor: spi_nor@0 {
				compatible = "jedec,spi-nor";     /* in zephyr/boards/seagate/legend/legend.dts:96 */
				reg = < 0x0 >;                    /* in zephyr/boards/seagate/legend/legend.dts:97 */
				spi-max-frequency = < 0x7a1200 >; /* in zephyr/boards/seagate/legend/legend.dts:98 */
				size = < 0x100000 >;              /* in zephyr/boards/seagate/legend/legend.dts:99 */
				jedec-id = [ 85 40 12 ];          /* in zephyr/boards/seagate/legend/legend.dts:111 */
				status = "okay";                  /* in zephyr/boards/seagate/legend/legend.dts:153 */

				/* node '/soc/spi@40003800/spi_nor@0/partitions' defined in zephyr/boards/seagate/legend/legend.dts:134 */
				partitions {
					compatible = "fixed-partitions"; /* in zephyr/boards/seagate/legend/legend.dts:135 */
					#address-cells = < 0x1 >;        /* in zephyr/boards/seagate/legend/legend.dts:136 */
					#size-cells = < 0x1 >;           /* in zephyr/boards/seagate/legend/legend.dts:137 */

					/* node '/soc/spi@40003800/spi_nor@0/partitions/partition@0' defined in zephyr/boards/seagate/legend/legend.dts:139 */
					product_info: partition@0 {
						label = "product-info"; /* in zephyr/boards/seagate/legend/legend.dts:140 */
						reg = < 0x0 0x1000 >;   /* in zephyr/boards/seagate/legend/legend.dts:141 */
					};

					/* node '/soc/spi@40003800/spi_nor@0/partitions/partition@1000' defined in zephyr/boards/seagate/legend/legend.dts:144 */
					led_das: partition@1000 {
						label = "led-das";       /* in zephyr/boards/seagate/legend/legend.dts:145 */
						reg = < 0x1000 0xf000 >; /* in zephyr/boards/seagate/legend/legend.dts:146 */
					};
				};
			};
		};

		/* node '/soc/timers@40001000' defined in zephyr/dts/arm/st/f0/stm32f070Xb.dtsi:67 */
		timers6: timers@40001000 {
			compatible = "st,stm32-timers"; /* in zephyr/dts/arm/st/f0/stm32f070Xb.dtsi:68 */
			reg = < 0x40001000 0x400 >;     /* in zephyr/dts/arm/st/f0/stm32f070Xb.dtsi:69 */
			clocks = < &rcc 0x1c 0x10 >,
			         < &rcc 0x8 0xff >;     /* in zephyr/dts/arm/st/f0/stm32f070Xb.dtsi:70 */
			resets = < &rctl 0x204 >;       /* in zephyr/dts/arm/st/f0/stm32f070Xb.dtsi:72 */
			interrupts = < 0x11 0x0 >;      /* in zephyr/dts/arm/st/f0/stm32f070Xb.dtsi:73 */
			interrupt-names = "global";     /* in zephyr/dts/arm/st/f0/stm32f070Xb.dtsi:74 */
			st,prescaler = < 0x0 >;         /* in zephyr/dts/arm/st/f0/stm32f070Xb.dtsi:75 */
			status = "disabled";            /* in zephyr/dts/arm/st/f0/stm32f070Xb.dtsi:76 */
		};

		/* node '/soc/timers@40001400' defined in zephyr/dts/arm/st/f0/stm32f070Xb.dtsi:79 */
		timers7: timers@40001400 {
			compatible = "st,stm32-timers"; /* in zephyr/dts/arm/st/f0/stm32f070Xb.dtsi:80 */
			reg = < 0x40001400 0x400 >;     /* in zephyr/dts/arm/st/f0/stm32f070Xb.dtsi:81 */
			clocks = < &rcc 0x1c 0x20 >,
			         < &rcc 0x8 0xff >;     /* in zephyr/dts/arm/st/f0/stm32f070Xb.dtsi:82 */
			resets = < &rctl 0x205 >;       /* in zephyr/dts/arm/st/f0/stm32f070Xb.dtsi:84 */
			interrupts = < 0x12 0x0 >;      /* in zephyr/dts/arm/st/f0/stm32f070Xb.dtsi:85 */
			interrupt-names = "global";     /* in zephyr/dts/arm/st/f0/stm32f070Xb.dtsi:86 */
			st,prescaler = < 0x0 >;         /* in zephyr/dts/arm/st/f0/stm32f070Xb.dtsi:87 */
			status = "disabled";            /* in zephyr/dts/arm/st/f0/stm32f070Xb.dtsi:88 */
		};
	};

	/* node '/cpus' defined in zephyr/dts/arm/st/f0/stm32f0.dtsi:27 */
	cpus {
		#address-cells = < 0x1 >; /* in zephyr/dts/arm/st/f0/stm32f0.dtsi:28 */
		#size-cells = < 0x0 >;    /* in zephyr/dts/arm/st/f0/stm32f0.dtsi:29 */

		/* node '/cpus/cpu@0' defined in zephyr/dts/arm/st/f0/stm32f0.dtsi:31 */
		cpu0: cpu@0 {
			device_type = "cpu";          /* in zephyr/dts/arm/st/f0/stm32f0.dtsi:32 */
			compatible = "arm,cortex-m0"; /* in zephyr/dts/arm/st/f0/stm32f0.dtsi:33 */
			reg = < 0x0 >;                /* in zephyr/dts/arm/st/f0/stm32f0.dtsi:34 */
		};
	};

	/* node '/memory@20000000' defined in zephyr/dts/arm/st/f0/stm32f0.dtsi:38 */
	sram0: memory@20000000 {
		compatible = "zephyr,memory-region",
		             "mmio-sram";            /* in zephyr/dts/arm/st/f0/stm32f0.dtsi:39 */
		zephyr,memory-region = "SRAM0";      /* in zephyr/dts/arm/st/f0/stm32f0.dtsi:40 */
		reg = < 0x20000000 0x4000 >;         /* in zephyr/dts/arm/st/f0/stm32f070Xb.dtsi:10 */
	};

	/* node '/clocks' defined in zephyr/dts/arm/st/f0/stm32f0.dtsi:43 */
	clocks {

		/* node '/clocks/clk-hse' defined in zephyr/dts/arm/st/f0/stm32f0.dtsi:44 */
		clk_hse: clk-hse {
			#clock-cells = < 0x0 >;            /* in zephyr/dts/arm/st/f0/stm32f0.dtsi:45 */
			compatible = "st,stm32-hse-clock"; /* in zephyr/dts/arm/st/f0/stm32f0.dtsi:46 */
			status = "disabled";               /* in zephyr/dts/arm/st/f0/stm32f0.dtsi:47 */
		};

		/* node '/clocks/clk-hsi' defined in zephyr/dts/arm/st/f0/stm32f0.dtsi:50 */
		clk_hsi: clk-hsi {
			#clock-cells = < 0x0 >;         /* in zephyr/dts/arm/st/f0/stm32f0.dtsi:51 */
			compatible = "fixed-clock";     /* in zephyr/dts/arm/st/f0/stm32f0.dtsi:52 */
			clock-frequency = < 0x7a1200 >; /* in zephyr/dts/arm/st/f0/stm32f0.dtsi:53 */
			status = "okay";                /* in zephyr/boards/seagate/legend/legend_stm32f070xb_25hdd.overlay:27 */
			phandle = < 0x13 >;             /* in zephyr/boards/seagate/legend/legend_stm32f070xb_25hdd.overlay:31 */
		};

		/* node '/clocks/clk-hsi14' defined in zephyr/dts/arm/st/f0/stm32f0.dtsi:57 */
		clk_hsi14: clk-hsi14 {
			#clock-cells = < 0x0 >;         /* in zephyr/dts/arm/st/f0/stm32f0.dtsi:58 */
			compatible = "fixed-clock";     /* in zephyr/dts/arm/st/f0/stm32f0.dtsi:59 */
			clock-frequency = < 0xd59f80 >; /* in zephyr/dts/arm/st/f0/stm32f0.dtsi:60 */
			status = "disabled";            /* in zephyr/dts/arm/st/f0/stm32f0.dtsi:61 */
		};

		/* node '/clocks/clk-lse' defined in zephyr/dts/arm/st/f0/stm32f0.dtsi:64 */
		clk_lse: clk-lse {
			#clock-cells = < 0x0 >;            /* in zephyr/dts/arm/st/f0/stm32f0.dtsi:65 */
			compatible = "st,stm32-lse-clock"; /* in zephyr/dts/arm/st/f0/stm32f0.dtsi:66 */
			clock-frequency = < 0x8000 >;      /* in zephyr/dts/arm/st/f0/stm32f0.dtsi:67 */
			driving-capability = < 0x0 >;      /* in zephyr/dts/arm/st/f0/stm32f0.dtsi:68 */
			status = "disabled";               /* in zephyr/dts/arm/st/f0/stm32f0.dtsi:69 */
		};

		/* node '/clocks/clk-lsi' defined in zephyr/dts/arm/st/f0/stm32f0.dtsi:72 */
		clk_lsi: clk-lsi {
			#clock-cells = < 0x0 >;       /* in zephyr/dts/arm/st/f0/stm32f0.dtsi:73 */
			compatible = "fixed-clock";   /* in zephyr/dts/arm/st/f0/stm32f0.dtsi:74 */
			clock-frequency = < 0x9c40 >; /* in zephyr/dts/arm/st/f0/stm32f0.dtsi:75 */
			status = "disabled";          /* in zephyr/dts/arm/st/f0/stm32f0.dtsi:76 */
		};

		/* node '/clocks/pll' defined in zephyr/dts/arm/st/f0/stm32f0.dtsi:79 */
		pll: pll {
			#clock-cells = < 0x0 >;              /* in zephyr/dts/arm/st/f0/stm32f0.dtsi:80 */
			compatible = "st,stm32f0-pll-clock"; /* in zephyr/dts/arm/st/f0/stm32f0.dtsi:81 */
			clocks = < &clk_hsi >;               /* in zephyr/boards/seagate/legend/legend_stm32f070xb_25hdd.overlay:31 */
			prediv = < 0x1 >;                    /* in zephyr/boards/seagate/legend/legend_stm32f070xb_25hdd.overlay:32 */
			mul = < 0x6 >;                       /* in zephyr/boards/seagate/legend/legend_stm32f070xb_25hdd.overlay:33 */
			status = "okay";                     /* in zephyr/boards/seagate/legend/legend_stm32f070xb_25hdd.overlay:34 */
			phandle = < 0x3 >;                   /* in zephyr/boards/seagate/legend/legend_stm32f070xb_25hdd.overlay:38 */
		};
	};

	/* node '/vref' defined in zephyr/dts/arm/st/f0/stm32f0.dtsi:375 */
	vref: vref {
		compatible = "st,stm32-vref";      /* in zephyr/dts/arm/st/f0/stm32f0.dtsi:376 */
		vrefint-cal-addr = < 0x1ffff7ba >; /* in zephyr/dts/arm/st/f0/stm32f0.dtsi:377 */
		vrefint-cal-mv = < 0xce4 >;        /* in zephyr/dts/arm/st/f0/stm32f0.dtsi:378 */
		io-channels = < &adc1 0x11 >;      /* in zephyr/dts/arm/st/f0/stm32f0.dtsi:379 */
		status = "disabled";               /* in zephyr/dts/arm/st/f0/stm32f0.dtsi:380 */
	};

	/* node '/smbus1' defined in zephyr/dts/arm/st/f0/stm32f0.dtsi:383 */
	smbus1: smbus1 {
		compatible = "st,stm32-smbus"; /* in zephyr/dts/arm/st/f0/stm32f0.dtsi:384 */
		#address-cells = < 0x1 >;      /* in zephyr/dts/arm/st/f0/stm32f0.dtsi:385 */
		#size-cells = < 0x0 >;         /* in zephyr/dts/arm/st/f0/stm32f0.dtsi:386 */
		i2c = < &i2c1 >;               /* in zephyr/dts/arm/st/f0/stm32f0.dtsi:387 */
		status = "disabled";           /* in zephyr/dts/arm/st/f0/stm32f0.dtsi:388 */
	};

	/* node '/dietemp' defined in zephyr/dts/arm/st/f0/stm32f030.dtsi:14 */
	die_temp: dietemp {
		compatible = "st,stm32c0-temp-cal"; /* in zephyr/dts/arm/st/f0/stm32f030.dtsi:15 */
		ts-cal1-addr = < 0x1ffff7b8 >;      /* in zephyr/dts/arm/st/f0/stm32f030.dtsi:16 */
		ts-cal1-temp = < 0x1e >;            /* in zephyr/dts/arm/st/f0/stm32f030.dtsi:17 */
		ts-cal-vrefanalog = < 0xce4 >;      /* in zephyr/dts/arm/st/f0/stm32f030.dtsi:18 */
		avgslope = "4.3";                   /* in zephyr/dts/arm/st/f0/stm32f030.dtsi:19 */
		io-channels = < &adc1 0x10 >;       /* in zephyr/dts/arm/st/f0/stm32f030.dtsi:20 */
		ntc;                                /* in zephyr/dts/arm/st/f0/stm32f030.dtsi:21 */
		status = "disabled";                /* in zephyr/dts/arm/st/f0/stm32f030.dtsi:22 */
	};

	/* node '/usbphy' defined in zephyr/dts/arm/st/f0/stm32f070.dtsi:55 */
	usb_fs_phy: usbphy {
		compatible = "usb-nop-xceiv"; /* in zephyr/dts/arm/st/f0/stm32f070.dtsi:56 */
		#phy-cells = < 0x0 >;         /* in zephyr/dts/arm/st/f0/stm32f070.dtsi:57 */
		phandle = < 0xe >;            /* in zephyr/dts/arm/st/f0/stm32f070.dtsi:48 */
	};

	/* node '/smbus2' defined in zephyr/dts/arm/st/f0/stm32f070Xb.dtsi:92 */
	smbus2: smbus2 {
		compatible = "st,stm32-smbus"; /* in zephyr/dts/arm/st/f0/stm32f070Xb.dtsi:93 */
		#address-cells = < 0x1 >;      /* in zephyr/dts/arm/st/f0/stm32f070Xb.dtsi:94 */
		#size-cells = < 0x0 >;         /* in zephyr/dts/arm/st/f0/stm32f070Xb.dtsi:95 */
		i2c = < &i2c2 >;               /* in zephyr/dts/arm/st/f0/stm32f070Xb.dtsi:96 */
		status = "disabled";           /* in zephyr/dts/arm/st/f0/stm32f070Xb.dtsi:97 */
	};

	/* node '/brd-id' defined in zephyr/boards/seagate/legend/legend.dts:27 */
	board_id: brd-id {
		compatible = "gpio-keys"; /* in zephyr/boards/seagate/legend/legend.dts:28 */

		/* node '/brd-id/brd_id_0' defined in zephyr/boards/seagate/legend/legend.dts:30 */
		brd_id0: brd_id_0 {
			label = "BRD_ID_0";         /* in zephyr/boards/seagate/legend/legend.dts:31 */
			gpios = < &gpioc 0xd 0x0 >; /* in zephyr/boards/seagate/legend/legend.dts:32 */
			zephyr,code = < 0xb >;      /* in zephyr/boards/seagate/legend/legend.dts:33 */
		};

		/* node '/brd-id/brd_id_1' defined in zephyr/boards/seagate/legend/legend.dts:36 */
		brd_id1: brd_id_1 {
			label = "BRD_ID_1";         /* in zephyr/boards/seagate/legend/legend.dts:37 */
			gpios = < &gpioc 0xe 0x0 >; /* in zephyr/boards/seagate/legend/legend.dts:38 */
			zephyr,code = < 0x2 >;      /* in zephyr/boards/seagate/legend/legend.dts:39 */
		};

		/* node '/brd-id/brd_id_2' defined in zephyr/boards/seagate/legend/legend.dts:42 */
		brd_id2: brd_id_2 {
			label = "BRD_ID_2";         /* in zephyr/boards/seagate/legend/legend.dts:43 */
			gpios = < &gpioc 0xf 0x0 >; /* in zephyr/boards/seagate/legend/legend.dts:44 */
			zephyr,code = < 0x3 >;      /* in zephyr/boards/seagate/legend/legend.dts:45 */
		};
	};

	/* node '/pwmleds' defined in zephyr/boards/seagate/legend/legend_stm32f070xb_25hdd.overlay:15 */
	led_pwm: pwmleds {
		compatible = "pwm-leds"; /* in zephyr/boards/seagate/legend/legend_stm32f070xb_25hdd.overlay:16 */
		label = "LED PWM";       /* in zephyr/boards/seagate/legend/legend_stm32f070xb_25hdd.overlay:17 */

		/* node '/pwmleds/pwm_led_0' defined in zephyr/boards/seagate/legend/legend_stm32f070xb_25hdd.overlay:19 */
		pwm_led0: pwm_led_0 {
			label = "Activity LED";             /* in zephyr/boards/seagate/legend/legend_stm32f070xb_25hdd.overlay:20 */
			pwms = < &pwm3 0x3 0x1312d00 0x0 >; /* in zephyr/boards/seagate/legend/legend_stm32f070xb_25hdd.overlay:21 */
		};
	};
};
